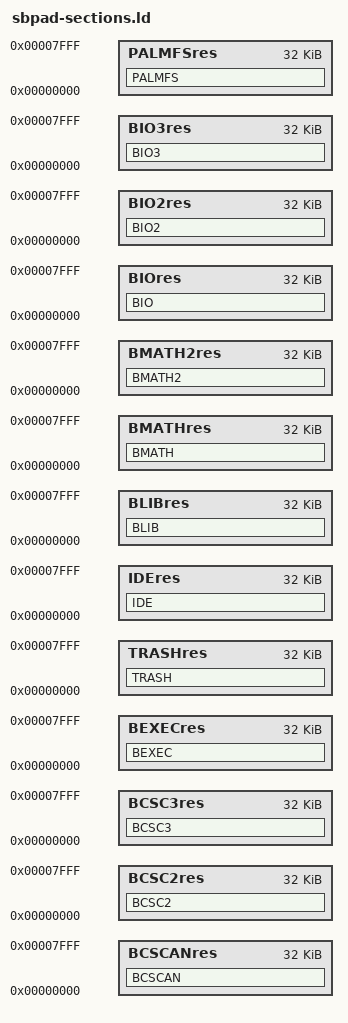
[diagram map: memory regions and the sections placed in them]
/* DO NOT EDIT!
   This file was automatically generated by m68k-palmos-multigen v2.3
   from sbpad.def  */

MEMORY
{
	BCSCANres : ORIGIN = 0x0, LENGTH = 32768
	BCSC2res : ORIGIN = 0x0, LENGTH = 32768
	BCSC3res : ORIGIN = 0x0, LENGTH = 32768
	BEXECres : ORIGIN = 0x0, LENGTH = 32768
	TRASHres : ORIGIN = 0x0, LENGTH = 32768
	IDEres : ORIGIN = 0x0, LENGTH = 32768
	BLIBres : ORIGIN = 0x0, LENGTH = 32768
	BMATHres : ORIGIN = 0x0, LENGTH = 32768
	BMATH2res : ORIGIN = 0x0, LENGTH = 32768
	BIOres : ORIGIN = 0x0, LENGTH = 32768
	BIO2res : ORIGIN = 0x0, LENGTH = 32768
	BIO3res : ORIGIN = 0x0, LENGTH = 32768
	PALMFSres : ORIGIN = 0x0, LENGTH = 32768
}

SECTIONS
{
	BCSCAN : { *(BCSCAN) } > BCSCANres
	BCSC2 : { *(BCSC2) } > BCSC2res
	BCSC3 : { *(BCSC3) } > BCSC3res
	BEXEC : { *(BEXEC) } > BEXECres
	TRASH : { *(TRASH) } > TRASHres
	IDE : { *(IDE) } > IDEres
	BLIB : { *(BLIB) } > BLIBres
	BMATH : { *(BMATH) } > BMATHres
	BMATH2 : { *(BMATH2) } > BMATH2res
	BIO : { *(BIO) } > BIOres
	BIO2 : { *(BIO2) } > BIO2res
	BIO3 : { *(BIO3) } > BIO3res
	PALMFS : { *(PALMFS) } > PALMFSres
}
